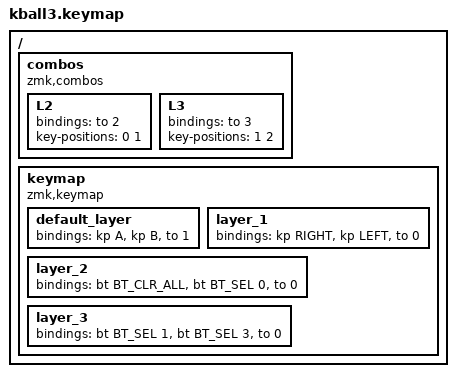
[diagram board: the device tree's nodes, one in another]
#include <dt-bindings/zmk/mouse.h>
#include <behaviors.dtsi>
#include <dt-bindings/zmk/bt.h>
#include <dt-bindings/zmk/keys.h>

/ {
    combos {
        compatible = "zmk,combos";

        L2 {
            bindings = <&to 2>;
            key-positions = <0 1>;
        };

        L3 {
            bindings = <&to 3>;
            key-positions = <1 2>;
        };
    };

    keymap {
        compatible = "zmk,keymap";

        default_layer {
            bindings = <
&kp A  &kp B  &to 1
            >;
        };

        layer_1 {
            bindings = <
&kp RIGHT  &kp LEFT  &to 0
            >;
        };

        layer_2 {
            bindings = <
&bt BT_CLR_ALL  &bt BT_SEL 0  &to 0
            >;
        };

        layer_3 {
            bindings = <
&bt BT_SEL 1  &bt BT_SEL 3  &to 0
            >;
        };
    };
};
